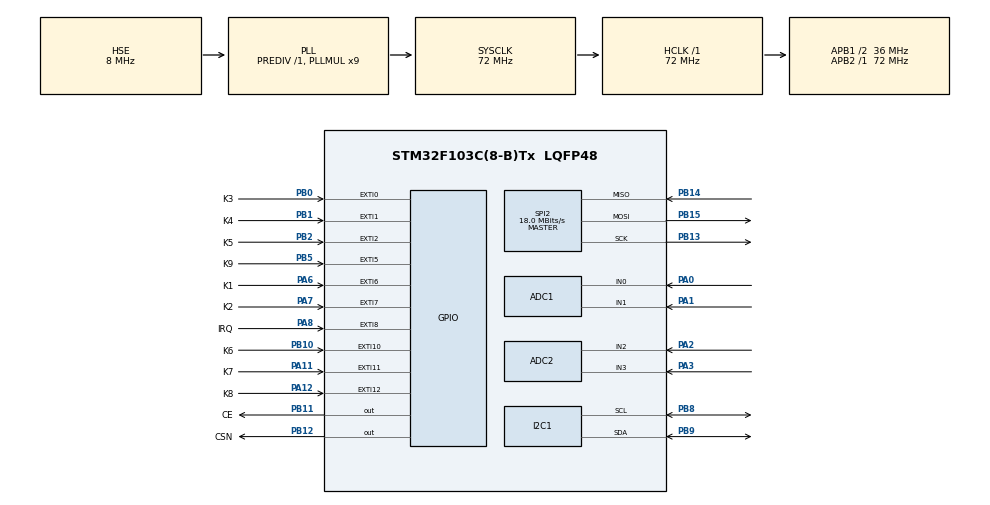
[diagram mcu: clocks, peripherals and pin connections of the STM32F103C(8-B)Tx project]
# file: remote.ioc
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ADC1.Channel-0\#ChannelRegularConversion=ADC_CHANNEL_1
ADC1.NbrOfConversionFlag=1
ADC1.Rank-0\#ChannelRegularConversion=1
ADC1.SamplingTime-0\#ChannelRegularConversion=ADC_SAMPLETIME_1CYCLE_5
ADC1.master=1
ADC2.Channel-0\#ChannelRegularConversion=ADC_CHANNEL_2
ADC2.NbrOfConversionFlag=1
ADC2.Rank-0\#ChannelRegularConversion=1
ADC2.SamplingTime-0\#ChannelRegularConversion=ADC_SAMPLETIME_1CYCLE_5
FREERTOS.Tasks01=defaultTask,0,128,StartDefaultTask,Default,NULL,Dynamic,NULL,NULL;remote_tesk,0,128,remote_task,As weak,NULL,Dynamic,NULL,NULL;key_read,-1,128,readkey,As weak,NULL,Dynamic,NULL,NULL;oled,0,128,oled_task,As weak,NULL,Dynamic,NULL,NULL
Mcu.Family=STM32F1
Mcu.Name=STM32F103C(8-B)Tx
Mcu.Package=LQFP48
NVIC.EXTI0_IRQn=true\:5\:0\:false\:false\:true\:true\:true\:true\:true
NVIC.EXTI15_10_IRQn=true\:5\:0\:false\:false\:true\:true\:true\:true\:true
NVIC.EXTI1_IRQn=true\:5\:0\:false\:false\:true\:true\:true\:true\:true
NVIC.EXTI2_IRQn=true\:5\:0\:false\:false\:true\:true\:true\:true\:true
NVIC.EXTI9_5_IRQn=true\:5\:0\:false\:false\:true\:true\:true\:true\:true
NVIC.PriorityGroup=NVIC_PRIORITYGROUP_4
NVIC.TIM4_IRQn=true\:15\:0\:false\:false\:true\:false\:false\:true\:true
NVIC.TimeBase=TIM4_IRQn
NVIC.TimeBaseIP=TIM4
PA0-WKUP.Signal=ADCx_IN0
PA1.Signal=ADCx_IN1
PA11.GPIO_Label=K7
PA11.GPIO_ModeDefaultEXTI=GPIO_MODE_IT_RISING_FALLING
PA11.Signal=GPXTI11
PA12.GPIO_Label=K8
PA12.GPIO_ModeDefaultEXTI=GPIO_MODE_IT_RISING_FALLING
PA12.Signal=GPXTI12
PA13.Mode=Serial_Wire
PA13.Signal=SYS_JTMS-SWDIO
PA14.Mode=Serial_Wire
PA14.Signal=SYS_JTCK-SWCLK
PA2.Signal=ADCx_IN2
PA3.Signal=ADCx_IN3
PA6.GPIO_Label=K1
PA6.GPIO_ModeDefaultEXTI=GPIO_MODE_IT_RISING_FALLING
PA6.Signal=GPXTI6
PA7.GPIO_Label=K2
PA7.GPIO_ModeDefaultEXTI=GPIO_MODE_IT_RISING_FALLING
PA7.Signal=GPXTI7
PA8.GPIO_Label=IRQ
PA8.GPIO_ModeDefaultEXTI=GPIO_MODE_IT_FALLING
PA8.Signal=GPXTI8
PB0.GPIO_Label=K3
PB0.GPIO_ModeDefaultEXTI=GPIO_MODE_IT_RISING_FALLING
PB0.Signal=GPXTI0
PB1.GPIO_Label=K4
PB1.GPIO_ModeDefaultEXTI=GPIO_MODE_IT_RISING_FALLING
PB1.Signal=GPXTI1
PB10.GPIO_Label=K6
PB10.GPIO_ModeDefaultEXTI=GPIO_MODE_IT_RISING_FALLING
PB10.Signal=GPXTI10
PB11.GPIO_Label=CE
PB11.Signal=GPIO_Output
PB12.GPIO_Label=CSN
PB12.Signal=GPIO_Output
PB13.Mode=Full_Duplex_Master
PB13.Signal=SPI2_SCK
PB14.Mode=Full_Duplex_Master
PB14.Signal=SPI2_MISO
PB15.Mode=Full_Duplex_Master
PB15.Signal=SPI2_MOSI
PB2.GPIO_Label=K5
PB2.GPIO_ModeDefaultEXTI=GPIO_MODE_IT_RISING_FALLING
PB2.Signal=GPXTI2
PB5.GPIO_Label=K9
PB5.GPIO_ModeDefaultEXTI=GPIO_MODE_IT_RISING_FALLING
PB5.Signal=GPXTI5
PB8.Mode=I2C
PB8.Signal=I2C1_SCL
PB9.Mode=I2C
PB9.Signal=I2C1_SDA
PD0-OSC_IN.Mode=HSE-External-Oscillator
PD0-OSC_IN.Signal=RCC_OSC_IN
PD1-OSC_OUT.Mode=HSE-External-Oscillator
PD1-OSC_OUT.Signal=RCC_OSC_OUT
ProjectManager.HeapSize=0x200
ProjectManager.StackSize=0x400
ProjectManager.TargetToolchain=MDK-ARM V5.32
RCC.ADCPresc=RCC_ADCPCLK2_DIV6
RCC.AHBFreq_Value=72000000
RCC.APB1CLKDivider=RCC_HCLK_DIV2
RCC.APB1Freq_Value=36000000
RCC.APB1TimFreq_Value=72000000
RCC.APB2Freq_Value=72000000
RCC.APB2TimFreq_Value=72000000
RCC.HCLKFreq_Value=72000000
RCC.PLLMUL=RCC_PLL_MUL9
RCC.PLLSourceVirtual=RCC_PLLSOURCE_HSE
RCC.SYSCLKFreq_VALUE=72000000
RCC.SYSCLKSource=RCC_SYSCLKSOURCE_PLLCLK
RCC.USBFreq_Value=72000000
SH.ADCx_IN0.0=ADC1_IN0,IN0
SH.ADCx_IN1.0=ADC1_IN1,IN1
SH.ADCx_IN2.0=ADC2_IN2,IN2
SH.ADCx_IN3.0=ADC2_IN3,IN3
SPI2.CalculateBaudRate=18.0 MBits/s
SPI2.Direction=SPI_DIRECTION_2LINES
SPI2.Mode=SPI_MODE_MASTER
SPI2.VirtualType=VM_MASTER
VP_FREERTOS_VS_CMSIS_V1.Mode=CMSIS_V1
VP_SYS_VS_tim4.Mode=TIM4
board=custom

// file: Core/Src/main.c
/* USER CODE BEGIN Header */
/**
  ******************************************************************************
  * @file           : main.c
  * @brief          : Main program body
  ******************************************************************************
  * @attention
  *
  * Copyright (c) 2026 STMicroelectronics.
  * All rights reserved.
  *
  * This software is licensed under terms that can be found in the LICENSE file
  * in the root directory of this software component.
  * If no LICENSE file comes with this software, it is provided AS-IS.
  *
  ******************************************************************************
  */
/* USER CODE END Header */
#include "main.h"
#include "cmsis_os.h"
#include "adc.h"
#include "i2c.h"
#include "spi.h"
#include "gpio.h"

/* USER CODE BEGIN Includes */
#include "oled.h"
/* USER CODE END Includes */

void SystemClock_Config(void);
void MX_FREERTOS_Init(void);

int main(void)
{

  /* MCU Configuration--------------------------------------------------------*/

  /* Reset of all peripherals, Initializes the Flash interface and the Systick. */
  HAL_Init();

  /* Configure the system clock */
  SystemClock_Config();

  /* Initialize all configured peripherals */
  MX_GPIO_Init();
  MX_I2C1_Init();
  MX_SPI2_Init();
  MX_ADC1_Init();
  MX_ADC2_Init();
  /* USER CODE BEGIN 2 */
  HAL_Delay(100);
  OLED_Init();
  /* USER CODE END 2 */

  /* Call init function for freertos objects (in cmsis_os2.c) */
  MX_FREERTOS_Init();

  /* Start scheduler */
  osKernelStart();

  /* We should never get here as control is now taken by the scheduler */

  /* Infinite loop */
  while (1)
  {

  }
}

void SystemClock_Config(void)
{
  RCC_OscInitTypeDef RCC_OscInitStruct = {0};
  RCC_ClkInitTypeDef RCC_ClkInitStruct = {0};
  RCC_PeriphCLKInitTypeDef PeriphClkInit = {0};

  /** Initializes the RCC Oscillators according to the specified parameters
  * in the RCC_OscInitTypeDef structure.
  */
  RCC_OscInitStruct.OscillatorType = RCC_OSCILLATORTYPE_HSE;
  RCC_OscInitStruct.HSEState = RCC_HSE_ON;
  RCC_OscInitStruct.HSEPredivValue = RCC_HSE_PREDIV_DIV1;
  RCC_OscInitStruct.HSIState = RCC_HSI_ON;
  RCC_OscInitStruct.PLL.PLLState = RCC_PLL_ON;
  RCC_OscInitStruct.PLL.PLLSource = RCC_PLLSOURCE_HSE;
  RCC_OscInitStruct.PLL.PLLMUL = RCC_PLL_MUL9;
  if (HAL_RCC_OscConfig(&RCC_OscInitStruct) != HAL_OK)
  {
    Error_Handler();
  }

  /** Initializes the CPU, AHB and APB buses clocks
  */
  RCC_ClkInitStruct.ClockType = RCC_CLOCKTYPE_HCLK|RCC_CLOCKTYPE_SYSCLK
                              |RCC_CLOCKTYPE_PCLK1|RCC_CLOCKTYPE_PCLK2;
  RCC_ClkInitStruct.SYSCLKSource = RCC_SYSCLKSOURCE_PLLCLK;
  RCC_ClkInitStruct.AHBCLKDivider = RCC_SYSCLK_DIV1;
  RCC_ClkInitStruct.APB1CLKDivider = RCC_HCLK_DIV2;
  RCC_ClkInitStruct.APB2CLKDivider = RCC_HCLK_DIV1;

  if (HAL_RCC_ClockConfig(&RCC_ClkInitStruct, FLASH_LATENCY_2) != HAL_OK)
  {
    Error_Handler();
  }
  PeriphClkInit.PeriphClockSelection = RCC_PERIPHCLK_ADC;
  PeriphClkInit.AdcClockSelection = RCC_ADCPCLK2_DIV6;
  if (HAL_RCCEx_PeriphCLKConfig(&PeriphClkInit) != HAL_OK)
  {
    Error_Handler();
  }
}

void HAL_TIM_PeriodElapsedCallback(TIM_HandleTypeDef *htim)
{
  if (htim->Instance == TIM4)
  {
    HAL_IncTick();
  }
}

void Error_Handler(void)
{
  __disable_irq();
  while (1)
  {
  }
}

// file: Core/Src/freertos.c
/* USER CODE BEGIN Header */
/**
  ******************************************************************************
  * File Name          : freertos.c
  * Description        : Code for freertos applications
  ******************************************************************************
  * @attention
  *
  * Copyright (c) 2026 STMicroelectronics.
  * All rights reserved.
  *
  * This software is licensed under terms that can be found in the LICENSE file
  * in the root directory of this software component.
  * If no LICENSE file comes with this software, it is provided AS-IS.
  *
  ******************************************************************************
  */
/* USER CODE END Header */

#include "FreeRTOS.h"
#include "task.h"
#include "main.h"
#include "cmsis_os.h"

/* USER CODE BEGIN Includes */
#include "remoter.h"
#include "oled_printf.h"
/* USER CODE END Includes */

osThreadId defaultTaskHandle;
osThreadId remote_teskHandle;
osThreadId key_readHandle;
osThreadId oledHandle;

void StartDefaultTask(void const * argument);
void remote_task(void const * argument);
void readkey(void const * argument);
void oled_task(void const * argument);

void MX_FREERTOS_Init(void); /* (MISRA C 2004 rule 8.1) */

/* GetIdleTaskMemory prototype (linked to static allocation support) */
void vApplicationGetIdleTaskMemory( StaticTask_t **ppxIdleTaskTCBBuffer, StackType_t **ppxIdleTaskStackBuffer, uint32_t *pulIdleTaskStackSize );

/* USER CODE BEGIN GET_IDLE_TASK_MEMORY */
static StaticTask_t xIdleTaskTCBBuffer;
static StackType_t xIdleStack[configMINIMAL_STACK_SIZE];

void vApplicationGetIdleTaskMemory( StaticTask_t **ppxIdleTaskTCBBuffer, StackType_t **ppxIdleTaskStackBuffer, uint32_t *pulIdleTaskStackSize )
{
  *ppxIdleTaskTCBBuffer = &xIdleTaskTCBBuffer;
  *ppxIdleTaskStackBuffer = &xIdleStack[0];
  *pulIdleTaskStackSize = configMINIMAL_STACK_SIZE;
  /* place for user code */
}
/* USER CODE END GET_IDLE_TASK_MEMORY */

void MX_FREERTOS_Init(void) {

  /* Create the thread(s) */
  /* definition and creation of defaultTask */
  osThreadDef(defaultTask, StartDefaultTask, osPriorityNormal, 0, 128);
  defaultTaskHandle = osThreadCreate(osThread(defaultTask), NULL);

  /* definition and creation of remote_tesk */
  osThreadDef(remote_tesk, remote_task, osPriorityNormal, 0, 128);
  remote_teskHandle = osThreadCreate(osThread(remote_tesk), NULL);

  /* definition and creation of key_read */
  osThreadDef(key_read, readkey, osPriorityBelowNormal, 0, 128);
  key_readHandle = osThreadCreate(osThread(key_read), NULL);

  /* definition and creation of oled */
  osThreadDef(oled, oled_task, osPriorityNormal, 0, 128);
  oledHandle = osThreadCreate(osThread(oled), NULL);

}

void StartDefaultTask(void const * argument)
{
  for(;;)
  {
    osDelay(1);
  }
}

__weak void remote_task(void const * argument)
{
}

__weak void readkey(void const * argument)
{
  for(;;)
  {
    osDelay(1);
  }
}

__weak void oled_task(void const * argument)
{
  for(;;)
  {
    osDelay(1);
  }
}
